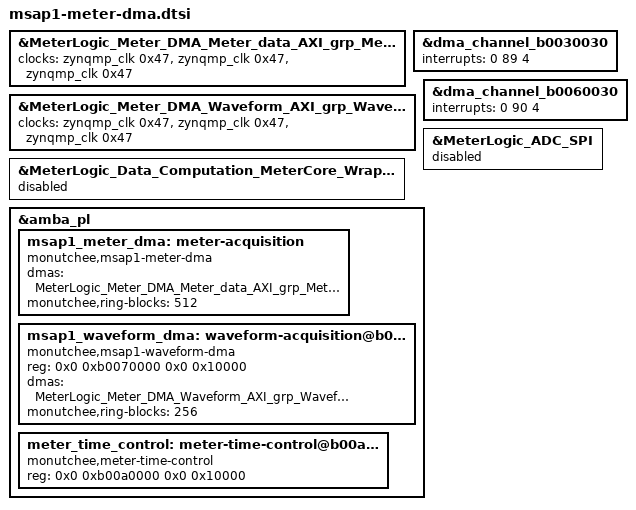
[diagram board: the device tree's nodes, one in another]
/* MSAP1 Linux meter-result DMA ownership. */
&MeterLogic_Meter_DMA_Meter_data_AXI_grp_Meter_data_DMA {
	clocks = <&zynqmp_clk 0x47>,
		 <&zynqmp_clk 0x47>,
		 <&zynqmp_clk 0x47>;
	clock-names = "m_axi_s2mm_aclk", "s_axi_lite_aclk", "m_axi_sg_aclk";
};

/* The S2MM interrupt is wired to pl_ps_irq0 GIC SPI 89. */
&dma_channel_b0030030 {
	interrupts = <0 89 4>;
};

/* Independent raw-waveform SG/S2MM channel on GIC SPI 90. */
&MeterLogic_Meter_DMA_Waveform_AXI_grp_Waveform_DMA {
	clocks = <&zynqmp_clk 0x47>,
		 <&zynqmp_clk 0x47>,
		 <&zynqmp_clk 0x47>;
	clock-names = "m_axi_s2mm_aclk", "s_axi_lite_aclk", "m_axi_sg_aclk";
};

&dma_channel_b0060030 {
	interrupts = <0 90 4>;
};

/* SPI and the consolidated MeterCore registers remain R5 core 0 owned. */
&MeterLogic_ADC_SPI {
	status = "disabled";
};

&MeterLogic_Data_Computation_MeterCore_Wrapper {
	status = "disabled";
};

/* Lopper extracts /amba_pl into the runtime overlay and renames it to &amba. */
&amba_pl {
	msap1_meter_dma: meter-acquisition {
		compatible = "monutchee,msap1-meter-dma";
		dmas = <&MeterLogic_Meter_DMA_Meter_data_AXI_grp_Meter_data_DMA 1>;
		dma-names = "rx";
		/*
		 * Harmonic spectra arrive as atomic 42-record bursts. 512 x 256-byte
		 * periods (128 KiB coherent) absorb several families while userspace
		 * completes one batched durable commit.
		 */
		monutchee,ring-blocks = <512>;
		status = "okay";
	};

	/*
	 * The driver owns the waveform DMA channel and its stream-control bank.
	 * Time correlation is intentionally isolated in meter-time-control below.
	 * Raw history remains in daemon-owned DDR.
	 *
	 * Ring depth is stated here rather than left to the driver default:
	 * 256 32832-byte blocks (~8 MiB coherent) give the daemon ~2 s of
	 * stall tolerance at 128 kSPS, where the previous 64-block ring gave
	 * only 0.512 s and was lapped in the field.
	 */
	msap1_waveform_dma: waveform-acquisition@b0070000 {
		compatible = "monutchee,msap1-waveform-dma";
		reg = <0x0 0xb0070000 0x0 0x10000>;
		dmas = <&MeterLogic_Meter_DMA_Waveform_AXI_grp_Waveform_DMA 1>;
		dma-names = "rx";
		monutchee,ring-blocks = <256>;
		status = "okay";
	};

	meter_time_control: meter-time-control@b00a0000 {
		compatible = "monutchee,meter-time-control";
		reg = <0x0 0xb00a0000 0x0 0x10000>;
		status = "okay";
	};
};
